# CC3220SF register map
Vendor: Texas Instruments; Series: Wireless Connectivity MCU; File version: 1
CPU: CM4 r1p0, little endian, no MPU, no FPU, 8 interrupt priority bits
Registers are 32-bit, read-write, reset 0x0 unless marked. A register's access mark holds for its fields unless they carry their own. Offsets are from the block's base; [hi:lo] are bit positions; 'fields as' and 'values as' point back to an identical list.

## STACKDIE_CTRL
Base 0x400F5000
0x00 STK_UP_RESET — Can be written only by Base Processor. Writing to this register will reset the stack processor reset will be de-asserted upon clearing this register.
0x04 SR_MASTER_PRIORITY — This register defines who among base processor and stack processor have highest priority for Sram Access. Can be written only by Base Processor.
  [1:0] PRIORITY — 00 : Equal Priority 01 : Stack Processor have priority 10 : Base Processor have priority 11 : Unused
0x08 STK_SR_ACC_CTL_BK2 — In Spinlock mode this Register defines who among base processor and stack processor have access to Sram Bank2 right now. In Handshake mode this Register defines who among base processor and stack processor have access to Sram Bank2 and Bank3 right now. Its Clear only register and is set by hardware. Lower bit can be cleared only by Base Processor and Upper bit Cleared only by the Stack processor.
0x0C BASE_UP_ACC_REQ_BK2 — In Spinlock mode whenever Base processor wants the access to Sram Bank2 it should request for it by writing into this register. It'll get interrupt whenever it is granted. In Handshake mode this bit will be set by Stack processor. Its a set only bit and is cleared by HW when the request is granted.
0x10 STK_UP_ACC_REQ_BK2 — In Spinlock mode Whenever Stack processor wants the access to Sram Bank2 it should request for it by writing into this register. It'll get interrupt whenever it is granted. In Handshake mode this bit will be set by the Base processor. Its a set only bit and is cleared by HW when the request is granted.
0x14 STK_SR_ACC_CTL_BK3 — Register defines who among base processor and stack processor have access to Sram Bank3 right now. Its Clear only register and is set by hardware. Lower bit can be cleared only by Base Processor and Upper bit Cleared only by the Stack processor.
0x18 BASE_UP_ACC_REQ_BK3 — In Spinlock mode whenever Base processor wants the access to Sram Bank3 it should request for it by writing into this register. It'll get interrupt whenever it is granted. In Handshake mode this bit will be set by Stack processor. Its a set only bit and is cleared by HW when the request is granted.
0x1C STK_UP_ACC_REQ_BK3 — In Spinlock mode Whenever Stack processor wants the access to Sram Bank3 it should request for it by writing into this register. It'll get interrupt whenever it is granted. In Handshake mode this bit will be set by the Base processor. Its a set only bit and is cleared by HW when the request is granted.
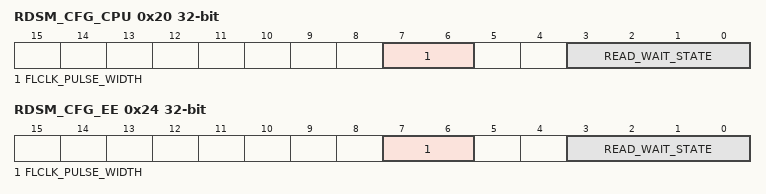
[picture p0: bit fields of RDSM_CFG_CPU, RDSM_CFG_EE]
0x20 RDSM_CFG_CPU — Read State Machine timing configuration register. Generally Bit 4 and 3 will be identical. For stacked die always 43 are 0 and 6:5 == 1 for 120Mhz.
  [7:6] FLCLK_PULSE_WIDTH — Bank Clock Hi Time 00 : HCLK pulse 01 : 1 cycle of HCLK 10 : 1.5 cycles of HCLK 11 : 2 cycles of HCLK
  [3:0] READ_WAIT_STATE — Number of wait states inserted
0x24 RDSM_CFG_EE — Read State Machine timing configuration register. Generally Bit 4 and 3 will be identical. For stacked die always 43 are 0 and 6:5 == 1 for 120Mhz.
  fields as RDSM_CFG_CPU
0x28 BASE_UP_IRQ_LOG — Reading this register Base procesor will able to know the reason for the interrupt. This is clear only register - set by HW upon an interrupt to Base processor and can be cleared only by BASE processor.
0x2C STK_UP_IRQ_LOG — Reading this register Stack procesor will able to know the reason for the interrupt. This is clear only register - set by HW upon an interrupt to Stack processor and can be cleared only by Stack processor.
0x30 STK_CLK_EN — Can be written only by base processor. Controls the enable pin of the cgcs for the clocks going to CM3 dft ctrl block and Sram.
0x34 SPIN_LOCK_MODE — Can be written only by the base processor. Decides the ram sharing mode :: handshake or Spinlock mode.
0x38 BUS_FAULT_ADDR — Stores the last bus fault address.
0x3C BUS_FAULT_CLR — write only registers on read returns 0.W Write 1 to clear the bust fault to store the new bus fault address
0x40 RESET_CAUSE — Reset cause value captured from the ICR_CLKRST block.
0x44 WDOG_TIMER_EVENT — Watchdog timer event value captured from the ICR_CLKRST block
0x48 DMA_REQ — To send Dma Request to bottom die.
0x4C SRAM_JUMP_OFFSET_ADDR — Address offset within SRAM to which CM3 should jump after reset.
0x50 SW_REG1 — These are sw registers for topdie processor and bottom die processor to communicate. Both can set and read these registers. In case of write clash bottom die's processor wins and top die processor access is ignored.
0x54 SW_REG2 — These are sw registers for topdie processor and bottom die processor to communicate. Both can set and read these registers. In case of write clash bottom die's processor wins and top die processor access is ignored.
0x58 FMC_SLEEP_CTL — By posting the request Flash can be put into low-power mode (Sleep) without powering down the Flash. Earlier (in Garnet) this was fully h/w controlled and the control for this was coming from SysCtl while entering into Cortex Deep-sleep mode. But for our device the D2D i/f doesnt support this. The Firmware has to program the register in the top-die for entering into this mode and wait for an interrupt.
0x5C MISC_CTL — Miscellanious control register.
0xFC SW_DFT_CTL — DFT control and status bits
0x100 PADN_CTL_0 — Mainly for For controlling the pads OEN pins. There are total 60 pads and hence 60 control registe i.e n value varies from 0 to 59. Here is the mapping for the pad_ctl register number and the functionality : 0 D2DPAD_DMAREQ1 1 D2DPAD_DMAREQ0 2 D2DPAD_INT2BASE 3 D2DPAD_PIOSC 4 D2DPAD_RST_N 5 D2DPAD_POR_RST_N 6 D2DPAD_HCLK 7 D2DPAD_JTAG_TDO 8 D2DPAD_JTAG_TCK 9 D2DPAD_JTAG_TMS 10 D2DPAD_JTAG_TDI 11-27 D2DPAD_FROMSTACK[D2D_FROMSTACK_SIZE -1:0] 28-56 D2DPAD_TOSTACK [D2D_TOSTACK_SIZE -1:0] 57-59 D2DPAD_SPARE [D2D_SPARE_PAD_SIZE -1:0] 0:00 ****************************************************************************
